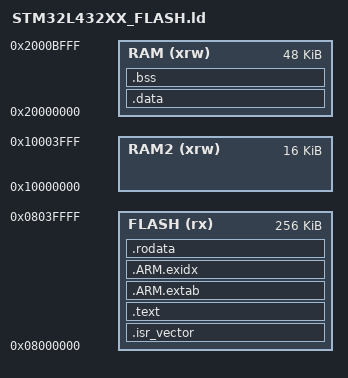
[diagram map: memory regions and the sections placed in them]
/* Entry Point */
ENTRY(Reset_Handler)

/* Highest address of the user mode stack */
_estack = ORIGIN(RAM) + LENGTH(RAM);    /* end of RAM */
/* Generate a link error if heap and stack don't fit into RAM */
_Min_Heap_Size = 0x200;      /* required amount of heap  */
_Min_Stack_Size = 0x400; /* required amount of stack */

/* Specify the memory areas */
MEMORY
{
RAM (xrw)      : ORIGIN = 0x20000000, LENGTH = 48K
RAM2 (xrw)      : ORIGIN = 0x10000000, LENGTH = 16K
FLASH (rx)      : ORIGIN = 0x8000000, LENGTH = 256K
}

/* Define output sections */
SECTIONS
{
  .isr_vector :
  {
    . = ALIGN(4);
    KEEP(*(.isr_vector)) /* Startup code */
    . = ALIGN(4);
  } > FLASH

  .text :
  {
    . = ALIGN(4);
    *(.text)
    *(.text*)
    . = ALIGN(4);

    /** BEGIN C RUNTIME LINKAGE */

    . = ALIGN(4);
    KEEP(*(.init))
    . = ALIGN(4);
    __preinit_array_start = .;
    KEEP (*(.preinit_array))
    __preinit_array_end = .;

    . = ALIGN(4);
    __init_array_start = .;
    KEEP (*(SORT(.init_array.*)))
    KEEP (*(.init_array))
    __init_array_end = .;
    . = ALIGN(4);
    KEEP(*(.fini))
    . = ALIGN(4);
    __fini_array_start = .;
    KEEP (*(.fini_array))
    KEEP (*(SORT(.fini_array.*)))
    __fini_array_end = .;
    . = ALIGN(4);
    KEEP (*crtbegin.o(.ctors))
    KEEP (*(EXCLUDE_FILE (*crtend.o) .ctors))
    KEEP (*(SORT(.ctors.*)))
    KEEP (*crtend.o(.ctors))

    . = ALIGN(4);
    KEEP (*crtbegin.o(.dtors))
    KEEP (*(EXCLUDE_FILE (*crtend.o) .dtors))
    KEEP (*(SORT(.dtors.*)))
    KEEP (*crtend.o(.dtors))
    . = ALIGN(4);
    _efixed = .;

    /** END C RUNTIME LINKAGE */

  } > FLASH

  /** ARM exception handling. ARM defines these sections for exception handling */
  .ARM.extab : {
      *(.ARM.extab* .gnu.linkonce.armextab.*)
  } > FLASH

  .ARM.exidx : {
    PROVIDE(__exidx_start = .);
    *(.ARM.exidx* .gnu.linkonce.armexidx.*)
    PROVIDE(__exidx_end = .);
  } > FLASH

  .rodata :
  {
    . = ALIGN(4);
    *(rodata)
    *(.rodata*)
    . = ALIGN(4);
  } > FLASH

  .data (NOLOAD) :
  {
    . = ALIGN(4);
    _sdata = .;
    *(.data .data.*)
    *(.ramfunc .ramfunc.*)
    . = ALIGN(4);
    _edata = .;
  } > RAM

  _sidata = LOADADDR(.data);

  .bss (NOLOAD) :
  {
    . = ALIGN(4);
    _sbss = .;
    *(.bss .bss.*)
    *(COMMON)
    . = ALIGN(4);
    _ebss = .;
  } > RAM
}


